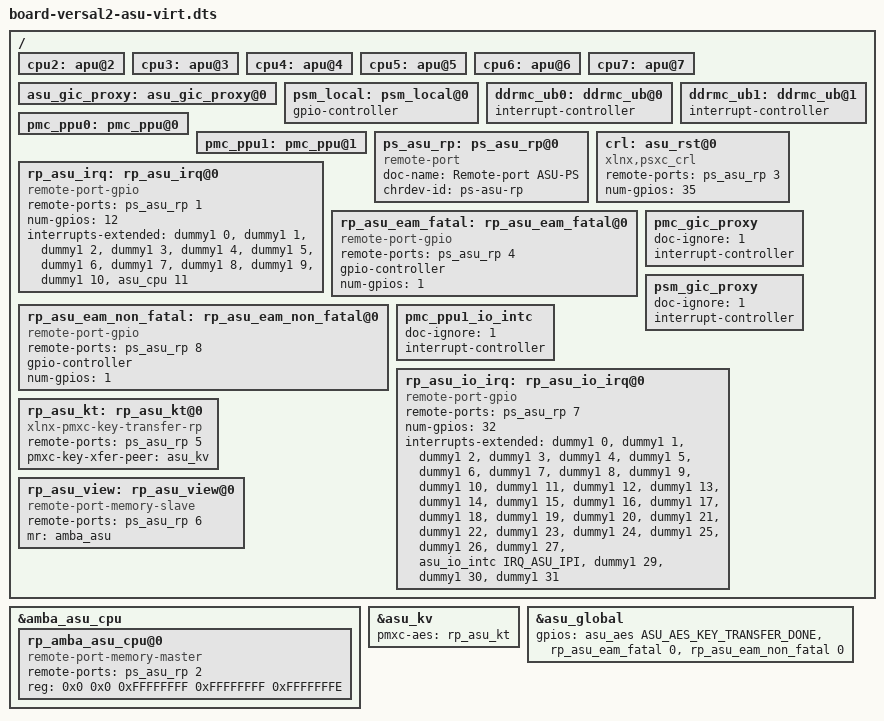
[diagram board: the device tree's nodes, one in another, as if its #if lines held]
/* Versal Gen 2 ASU Emulation
 *
 * Copyright (c) 2023, AMD Inc
 * All rights reserved.
 *
 * SPDX-License-Identifier: BSD-3-Clause
 */

/********ASU Features********
 * 256KB Firmware RAM or 128KB Data RAM
 * XPPU protects the ram access
 * 64K Bank of Data ROM has ASU only access
 * Security-subsystem
 * 	Key Vault
 * 	AES
 * 	SHA2/3
 * 	ECDSA/RSA
 * 	TRNG
 * 	DMA
 * Microblze RISCV Processor
 * MDM
 * Microblaze IO Module
 * ASU Local/Global Regs
 */

/dts-v1/;

#define VERSAL2_DEV
#define VERSAL_PSX
#define VERSAL_NET
#define VERSAL_NPI_OVERRIDE

#include "versal2-xc2ve3858-npi-memmap.dtsi"
#include "versal.dtsh"
#include "interconnect.dtsh"
#include "versal2-icnt.dtsi"
#include "versal2-asu-cpu.dtsi"

#ifndef MULTI_ARCH
#include "versal-memmap.dtsh"
#include "versal-pmc.dtsi"
#include "versal-ddrmc.dtsi"
#include "versal-ps-iou.dtsi"
#include "versal2-pmx-shared-overlay.dtsi"
#include "versal-pmx-shared-overlay.dtsi"
#include "versal-pmx-system-overlay.dtsi"
#include "versal2-pmxc-system-overlay.dtsi"
#include "versal2-mmi.dtsi"
#else
#include "versal-icnt.dtsi"
#include "versal-rams.dtsi"
#endif
#include "versal2-rams.dtsi"
#include "versal2-asu.dtsi"

#ifndef MULTI_ARCH
&crl {
	compatible = "xlnx,psxc_crl";
};
#endif

/ {
	MEM_REGION(ddr, 0x0, MM_DDR, 0x00000000, MM_DDR_SIZE, &ddr_mem)  // 2 GB

	/* Dummy APUs.  */
	cpu2: apu@2 { };
	cpu3: apu@3 { };
	cpu4: apu@4 { };
	cpu5: apu@5 { };
	cpu6: apu@6 { };
	cpu7: apu@7 { };
	asu_gic_proxy: asu_gic_proxy@0 { };
	psm_local: psm_local@0 {
		gpio-controller;
		#gpio-cells = <1>;
	 };
#ifndef HAVE_DDRMC_CPUS
	ddrmc_ub0: ddrmc_ub@0 {
		#interrupt-cells = <1>;
		interrupt-controller;
	};
	ddrmc_ub1: ddrmc_ub@1 {
		#interrupt-cells = <1>;
		interrupt-controller;
	};
#endif
	pmc_ppu0: pmc_ppu@0 {
		#interrupt-cells = <1>;
	};
	pmc_ppu1: pmc_ppu@1 {
		#interrupt-cells = <1>;
	};
#ifdef MULTI_ARCH
	ps_asu_rp: ps_asu_rp@0 {
		doc-name = "Remote-port ASU-PS";
		compatible = "remote-port";
		chrdev-id = "ps-asu-rp";
	};
	rp_asu_irq: rp_asu_irq@0 {
		compatible = "remote-port-gpio";
		remote-ports = <&ps_asu_rp 1>;
		num-gpios = <12>;
		interrupts-extended = <  &dummy1 0
					 &dummy1 1
					 &dummy1 2
					 &dummy1 3
					 &dummy1 4
					 &dummy1 5
					 &dummy1 6
					 &dummy1 7
					 &dummy1 8
					 &dummy1 9
					 &dummy1 10
					 &asu_cpu 11 >;
	};
	crl: asu_rst@0 {
		compatible = "remote-port-gpio";
		remote-ports = <&ps_asu_rp 3>;
		#gpio-cells = <1>;
		num-gpios = <35>;
	};
	rp_asu_eam_fatal: rp_asu_eam_fatal@0 {
		compatible = "remote-port-gpio";
		remote-ports = <&ps_asu_rp 4>;
		#gpio-cells = <1>;
		gpio-controller;
		num-gpios = <1>;
	};
	rp_asu_eam_non_fatal: rp_asu_eam_non_fatal@0 {
		compatible = "remote-port-gpio";
		remote-ports = <&ps_asu_rp 8>;
		#gpio-cells = <1>;
		gpio-controller;
		num-gpios = <1>;
	};
	pmc_gic_proxy: pmc_gic_proxy {
		doc-ignore = <1>;
		#interrupt-cells = <3>;
		interrupt-controller;
	};
	psm_gic_proxy: psm_gic_proxy {
		doc-ignore = <1>;
		#interrupt-cells = <3>;
		interrupt-controller;
	};
	pmc_ppu1_io_intc: pmc_ppu1_io_intc {
		doc-ignore = <1>;
		#interrupt-cells = <1>;
		interrupt-controller;
	};
	/*
	 * ASU IO module interrupt inputs raised in the PS instance. Only the
	 * ASU IPI doorbell is wired up, the remaining sources are local.
	 */
	rp_asu_io_irq: rp_asu_io_irq@0 {
		compatible = "remote-port-gpio";
		remote-ports = <&ps_asu_rp 7>;
		num-gpios = <32>;
		interrupts-extended = <  &dummy1 0
					 &dummy1 1
					 &dummy1 2
					 &dummy1 3
					 &dummy1 4
					 &dummy1 5
					 &dummy1 6
					 &dummy1 7
					 &dummy1 8
					 &dummy1 9
					 &dummy1 10
					 &dummy1 11
					 &dummy1 12
					 &dummy1 13
					 &dummy1 14
					 &dummy1 15
					 &dummy1 16
					 &dummy1 17
					 &dummy1 18
					 &dummy1 19
					 &dummy1 20
					 &dummy1 21
					 &dummy1 22
					 &dummy1 23
					 &dummy1 24
					 &dummy1 25
					 &dummy1 26
					 &dummy1 27
					 &asu_io_intc IRQ_ASU_IPI
					 &dummy1 29
					 &dummy1 30
					 &dummy1 31 >;
	};
	/*
	 * ASU key transfer towards the PMXC AES engine, which lives in the
	 * PS instance. Carries asu_ready() out, send_key() and done() back.
	 */
	rp_asu_kt: rp_asu_kt@0 {
		compatible = "xlnx-pmxc-key-transfer-rp";
		remote-ports = <&ps_asu_rp 5>;
		pmxc-key-xfer-peer = <&asu_kv>;
	};
	/*
	 * The ASU block (registers, IRAM and DRAM) is modelled here, so give
	 * the PS instance a view of it for the APU and the PMC.
	 */
	rp_asu_view: rp_asu_view@0 {
		compatible = "remote-port-memory-slave";
		remote-ports = <&ps_asu_rp 6>;
		mr = <&amba_asu>;
	};
#endif
};

#ifdef MULTI_ARCH
/*
 * The rest of the system is modelled in the PS instance. Give every ASU
 * master - the RISC-V core and the ASU DMAs - a view of it by making
 * remote-port the background of the ASU master bus. It sits below the
 * amba/amba_asu backgrounds (-1) so that local ASU devices always win and
 * only addresses nothing here claims, OCM in particular, go to the PS.
 */
&amba_asu_cpu {
	rp_amba_asu_cpu@0 {
		compatible = "remote-port-memory-master";
		remote-ports = <&ps_asu_rp 2>;
		reg = <0x0 0x0 0xFFFFFFFF 0xFFFFFFFF 0xFFFFFFFE /* -2 */>;
	};
};

&asu_kv {
	pmxc-aes = <&rp_asu_kt>;
};

/*
 * asu_global's unnamed gpios list is an FDT client:
 *   [0] key-xfer-done   <- asu_aes (local)
 *   [1] fatal-error     -> lpd_slcr eam-err-in[group 3 bit 4]
 *   [2] non-fatal-error -> lpd_slcr eam-err-in[group 3 bit 5]
 * The EAM inputs belong to the LPD error aggregator in the PS instance,
 * reach them over remote-port.
 */
&asu_global {
	gpios = <&asu_aes ASU_AES_KEY_TRANSFER_DONE>,
		<&rp_asu_eam_fatal 0>,
		<&rp_asu_eam_non_fatal 0>;
};
#endif
